# ET6801 register map
Vendor: ETMCU Inc.; File version: v0.0.1
CPU: CM7 r2p1, little endian, MPU, FPU, I-cache, D-cache, ITCM, DTCM, 4 interrupt priority bits
Registers are 32-bit, read-write, reset 0x0 unless marked. A register's access mark holds for its fields unless they carry their own. Offsets are from the block's base; [hi:lo] are bit positions; lines under a group give offsets from that group; {n}, {i} and the like mark numbered series.

## PFLASH — Provide an overview of the purpose and functionality of the peripheral: efc_cfg_pflash
Base 0x40603000
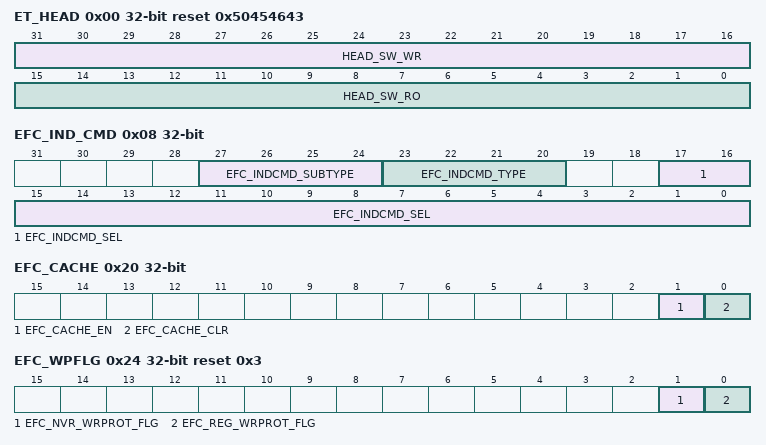
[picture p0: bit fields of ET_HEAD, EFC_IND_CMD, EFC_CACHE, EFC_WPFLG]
0x00 ET_HEAD reset 0x50454643
  [31:16] HEAD_SW_WR — 软件测试读写寄存器，硬件无访问
  [15:0] HEAD_SW_RO ro — 软件只读上报寄存器，硬件无访问,PEFC的ASICII 码表示
0x04 EFC_MEM_BASE
  [31:0] EFC_MEM_BASE_ADDR — EFC模块数据空间在系统的偏移地址
0x08 EFC_IND_CMD
  [27:24] EFC_INDCMD_SUBTYPE — sub选择类型； 0: NVR_CFG； 1: NVR； 2: RDN； 3: Main； 4: Main+RDN; //只在chip/block擦除时才能配置，并且block擦除不能选择Block retry擦除 5: Main+RDN+NVR; //只在chip擦除时才能配置 others: reserved.
  [23:20] EFC_INDCMD_TYPE — 指令类型： 0:Write; 1:Sector擦除; 2:Sector retry擦除; 3:Block擦除; 4:Block retry擦除;//只在所选Block区域无Bad Sector（即无RDN替换）时才能选择，并且不能选择Main+RDN 5:Chip擦除; 6:Normal Read; 7:Recall Read; 8:VREAD0; 9:VREAD1 10:VREAD1 check for Sector; 11:VREAD1 check for Block; 12:Sread0; 13:Sread1; default: NA；
  [17:0] EFC_INDCMD_SEL — 地址选择： 当指令类型为Read或Write时，该域为8byte单位的地址； 当指令类型为Sector/Block擦除或VREAD1时，该域为8byte单位的地址； 当指令类型为Chip擦除时，固定为0； 当sub选择类型==0: NVR_CFG时，该域为16byte单位的地址; 当sub选择类型==2: RDN时，该域为8byte单位的地址，该域为[17:14]: 4'b0001：选择RDN0，4'b0010：选择RDN1；4'b0100：选择RDN2，4'b1000：选择RDN3，[7:0]选择RDN Sector内部地址；其它bit不关注; 当sub选择类型==2:MAIN_RDN且当选择类型==3:Block擦除时，该域为8byte单位的地址，该域为[11:8]: 4'bxxx1：选择RDN0，4'bxx1x：选择RDN1；4'bx1xx：选择RDN2，4'b1xxx：选择RDN3，可同时选择多个RDN，[17:12]选择Block地址；其它bit不关注
0x0C EFC_IND_STS ro reset 0x1
  [1:0] EFC_INDIRECT_STS — 状态返回，只读： 0: 正在操作；1: 操作完成(OK)；2: 操作完成(ERR)；other: Reserved。 硬件也会查看该状态，在正在操作过程中，不会接受下一个指令，并会上报不一致错误；
0x10 EFC_IND_WD0
  [31:0] EFC_INDIRECT_WDATA0 — 低32bit写数据，如果涉及到byte级的操作，软件写入该寄存器时，不操作部分置1
0x14 EFC_IND_WD1
  [31:0] EFC_INDIRECT_WDATA1 — 高32bit写数据，如果涉及到byte级的操作，软件写入该寄存器时，不操作部分置1
0x18 EFC_IND_RD0 ro
  [31:0] EFC_INDIRECT_RDATA0 — 低32bit返回数据
0x1C EFC_IND_RD1 ro
  [31:0] EFC_INDIRECT_RDATA1 — 高32bit返回数据
0x20 EFC_CACHE
  [1] EFC_CACHE_EN — Cache使能； 0: Cache功能不打开； 1: Cache功能打开；
  [0] EFC_CACHE_CLR — Cache清空，硬件自清零； 0: Cache不清空； 1: Cache清空，下一拍硬件自清零；
0x24 EFC_WPFLG reset 0x3
  [1] EFC_NVR_WRPROT_FLG — NVR写保护标记，软件写1，硬件写0
  [0] EFC_REG_WRPROT_FLG — 寄存器写保护标记，软件写1，硬件写0
0x28 EFC_REG_KEY1
  [31:0] EFC_REG_KEY1 — 寄存器写保护KEY1，硬件自清零
0x2C EFC_REG_KEY2
  [31:0] EFC_REG_KEY2 — 寄存器写保护KEY2，硬件自清零
0x30 EFC_NVR_KEY1
  [31:0] EFC_NVR_KEY1 — NVR写保护KEY1，硬件自清零
0x34 EFC_NVR_KEY2
  [31:0] EFC_NVR_KEY2 — NVR写保护KEY2，硬件自清零
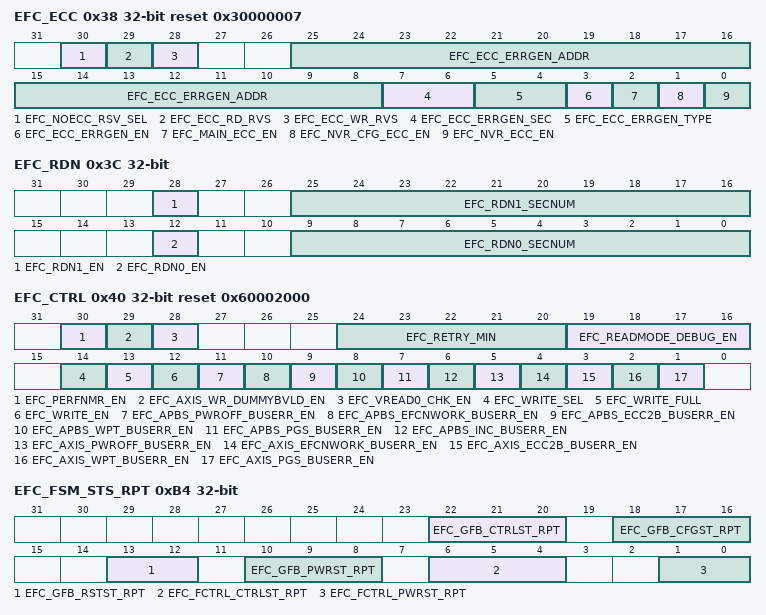
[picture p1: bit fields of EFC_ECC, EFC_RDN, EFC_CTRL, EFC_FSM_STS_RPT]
0x38 EFC_ECC reset 0x30000007
  [30] EFC_NOECC_RSV_SEL — ECC功能使能关闭时，8bit8全1插入位置选择： 0:除RSV3bi外，最高8bit，即3bit RSV+8bit ECC+ 64bit DATA； 1:最低8bit，即3bit RSV+64bit DATA+8bit ECC；
  [29] EFC_ECC_RD_RVS — ECC读翻转开启使能；
  [28] EFC_ECC_WR_RVS — ECC写翻转开启使能； Note:ECC读写翻转功能需要同时使能和不使能，并且在开启ECC写入数据之后，必须首先擦除数据才能修改，在开启ECC读写翻转时，可对擦除后的地址直接读取并且不会触发ECC错误告警。
  [25:8] EFC_ECC_ERRGEN_ADDR — ECC错误注入对应地址
  [7:6] EFC_ECC_ERRGEN_SEC — 地址对应sector范围； 1: NVR； 3: Main； other：reserved
  [5:4] EFC_ECC_ERRGEN_TYPE — ECC错误注入类型： 0：单bit错误； 1：2bit错误； other：更多bit错误；
  [3] EFC_ECC_ERRGEN_EN — ECC错误注入使能 1'b0：不打开ECC错误注入； 1'b1：打开ECC错误注入；
  [2] EFC_MAIN_ECC_EN — Main空间ECC功能使能开关； 0: ECC功能不使能； 1: ECC功能使能； Note：当使能注错功能时，对应注错地址需要先进行打开ecc使能后编程初始化，以确保注错地址本身存储的数据是ecc正确，否则上报的注错地址，不确定是其本身存储的数据ecc错误上报，还是注错导致的ecc错误地址上报；或者同时开启ECC读写翻转
  [1] EFC_NVR_CFG_ECC_EN — NVR_CFG空间ECC功能使能开关； 0: ECC功能不使能； 1: ECC功能使能； Note：NVR_CFG空间必须奇偶ROW对应地址的数据一致，对应bit才能读出确定值。
  [0] EFC_NVR_ECC_EN — NVR空间ECC功能使能开关； 0: ECC功能不使能； 1: ECC功能使能；
0x3C EFC_RDN
  [28] EFC_RDN1_EN — Redundancy sector的使能开关; 0: Redundancy sector使能关闭; 1: Redundancy sector使能打开；
  [25:16] EFC_RDN1_SECNUM — RDN1对应的Main空间sector number
  [12] EFC_RDN0_EN — Redundancy sector的使能开关; 0: Redundancy sector使能关闭; 1: Redundancy sector使能打开；
  [9:0] EFC_RDN0_SECNUM — RDN0对应的Main空间sector number
0x40 EFC_CTRL reset 0x60002000
  [30] EFC_PERFNMR_EN — EFC数据总线读性能模式使能； 0：数据总线读等待FLASH时钟上升沿进入读状态； 1：数据总线读提前FLASH时钟上升沿两个EFC时钟周期进入读状态；
  [29] EFC_AXIS_WR_DUMMYBVLD_EN — 数据总线写返回dummy bvlid使能； 0：数据总线写不返回dummy bvlid，数据写入FLASH之后再返回bvlid； 1：数据总线写命令接收后直接返回dummy bvlid；
  [28] EFC_VREAD0_CHK_EN — AXI/APB总线对FLASH编程后自动VRAD0读CHECK使能 0: 不进行VRAD0读CHECK； 1: 进行VRAD0读CHECK；
  [24:20] EFC_RETRY_MIN — 配置Flash retry擦除的最少次数；
  [19:16] EFC_READMODE_DEBUG_EN — AXI读FLASH替换为VREAD0/1、SREAD0/1读使能； 4'b0000: AXI读不进行替换，AXI为Normal READ； 4'b0001: AXI读替换为VREAD0； 4'b0010: AXI读替换为VREAD1； 4'b0100: AXI读替换为SREAD0； 4'b1000: AXI读替换为SREAD1； others: AXI读不进行替换
  [14] EFC_WRITE_SEL — FLASH写36bit选择； 0:写低36bit有效数据，高36bit写全1； 1:写高36bit有效数据，低36bit写全1； 注：，cfg_efc_write_full配置为0，硬件一次写36bit有效数据时有效，并且软件对应为AXI 8Bytes地址的低36bits；
  [13] EFC_WRITE_FULL — FLASH全写72bit使能； 0：硬件一次写36bit有效数据，另外36bit写全1； 1: 硬件一次性写72bit有效数据；
  [12] EFC_WRITE_EN — 配置EFC允许对Flash（Main / Redundancy）进行写/擦除操作； 0: 不允许对Flash进行写/擦除操作； 1: 允许对Flash进行写/擦除操作；
  [11] EFC_APBS_PWROFF_BUSERR_EN — 配置总线错误产生使能； 0: 在Flash未工作时的后续操作，APB总线不反馈Error Resp； 1: 在Flash未工作时的后续操作，APB总线反馈Error Resp；
  [10] EFC_APBS_EFCNWORK_BUSERR_EN — 配置总线错误产生使能； 0: 在EFC未工作时的后续操作，APB总线不反馈Error Resp； 1: 在EFC未工作时的后续操作，APB总线反馈Error Resp；
  [9] EFC_APBS_ECC2B_BUSERR_EN — 配置总线错误产生使能； 0: 在EFC未工作时的后续操作，APB总线不反馈Error Resp； 1: 在EFC未工作时的后续操作，APB总线反馈Error Resp；
  [8] EFC_APBS_WPT_BUSERR_EN — 配置总线错误产生使能； 0: 在发生wrp错误时，APB总线不反馈Error Resp； 1: 发生wrp错误时，APB总线反馈Error Resp；
  [7] EFC_APBS_PGS_BUSERR_EN — 配置总线错误产生使能； 0: 在发生pgs错误时，APB总线不反馈Error Resp； 1: 发生pgs错误时，APB总线反馈Error Resp；
  [6] EFC_APBS_INC_BUSERR_EN — 配置总线错误产生使能； 0: 在发生inc错误时，APB总线不反馈Error Resp； 1: 发生inc错误时，APB总线反馈Error Resp；
  [5] EFC_AXIS_PWROFF_BUSERR_EN — 数据总线错误产生使能； 0: 在Flash未工作时的后续操作，AXI总线不反馈Error Resp； 1: 在Flash未工作时的后续操作，AXI总线反馈Error Resp；
  [4] EFC_AXIS_EFCNWORK_BUSERR_EN — 数据总线错误产生使能； 0: 在EFC未工作时的后续操作，AXI总线不反馈Error Resp； 1: 在EFC未工作时的后续操作，AXI总线反馈Error Resp；
  [3] EFC_AXIS_ECC2B_BUSERR_EN — 数据总线错误产生使能； 0: 在EFC未工作时的后续操作，AXI总线不反馈Error Resp； 1: 在EFC未工作时的后续操作，AXI总线反馈Error Resp；
  [2] EFC_AXIS_WPT_BUSERR_EN — 数据总线错误产生使能； 0: 在发生wrp错误时，AXI总线不反馈Error Resp； 1: 发生wrp错误时，AXI总线反馈Error Resp；
  [1] EFC_AXIS_PGS_BUSERR_EN — 数据总线错误产生使能； 0: 在发生pgs错误时，AXI总线不反馈Error Resp； 1: 发生pgs错误时，AXI总线反馈Error Resp；
0x44 EFC_SYSBOOT reset 0x3E800
  [31:0] EFC_BOOT_TIMEOUT_MAX — Flash自启动最大超时设置； 默认为25MHz工作时钟、flash 25M timing参数配置下，启动时间的2倍；启动时间约72us，总长按80us计算，也就是在25MHz工作时钟下160us所占的cycle数，为4000；并且最快控制器工作在200M（time_out的计数器以最快频率计数），而颗粒处工作在25M（返回时间最慢）时，以时钟偏差50%角度设置该time_out的conter值，也不会超时， cfg_efc_boot_timeout_max=4000*(200M/25M)*(100M/12.5M)=128000;
0x48 EFC_INT_EN reset 0x204000
  [21:0] EFC_INT_EN — bit[14] - boot_timeout默认使能 bit[21] -- setcfg_fail默认使能
0x4C EFC_INT_MASK reset 0x280000
  [21:0] EFC_INT_MASK — bit[19] -- axim_cmd_err 默认mask，只做告警使用 bit[21] -- setcfg_fail默认mask，只做告警使用
0x50 EFC_INT_FORCE_IND
  [21:0] EFC_INT_FORCE_IND
0x54 EFC_INT_CLR
  [21:0] EFC_INT_CLR
0x58 EFC_INT_RAW_RPT ro
  [21:0] EFC_INT_RAW
0x5C EFC_INT_STATUS_RPT ro
  [21:0] EFC_INT_STATUS
{0x60+4i} EFC_DEBUG[{i}] (i=0..18) group — CFG_EFC_DEBUG
  0x00 DEBUG ro
    [31:0] EFC_DEBUG_INFO
0xAC EFC_DBG_STS ro
  [31:0] EFC_DBG_STS — [31:24] - intrd_rsved_cnt[7:0] [18:16] - intwr_rsved_cnt[2:0] [15:8] - busrd_rsved_cnt[7:0] [7:6] - s40_fctrl_idle - Flash无操作 [2:0] - buswr_rsved_cnt[2:0]
0xB0 EFC_RSV
  [31:0] EFC_RSVED — reserved register
0xB4 EFC_FSM_STS_RPT ro
  [22:20] EFC_GFB_CTRLST_RPT — EFC_GFB模块CTRL状态，只读： 0：等待EFC GFB POWER&RESET启动结束（WAITNG） 1：空闲（IDLE）； 2：写（WR）； 3：写RESP握手（WRESP）； 4：读（RD）； 5：擦除/VREAD RESP握手（BRESP）；
  [18:16] EFC_GFB_CFGST_RPT — EFC_GFB模块CFG_PROC状态，只读: 0：空闲（IDLE）； 1：APB间接读（READ）； 2：APB间接写（WRITE）； 3：APB全片擦除（ALLFCE）； other：APB间接sector/block/chip擦除、Vread1检查（OTHER）。
  [13:12] EFC_GFB_RSTST_RPT — EFC_GFB模块RESET状态，只读： 0：空闲（IDLE）； other：正常工作（WORKING）。
  [10:8] EFC_GFB_PWRST_RPT — EFC_GFB模块POWER上电状态，只读： 0：掉电（POWER OFF）； 1：读NVR_CFG（RD NVRC）； 2：写CFG寄存器（SETC）； 3：读CFG寄存器（RDC）；（车规FLASH MACRO新增操作） other：正常工作（WORKING）。
  [6:4] EFC_FCTRL_CTRLST_RPT — S40_FCTRL模块CTRL状态，只读： 0：空闲（IDLE）； 1：FLASH读（READ）； 2：FLASH写（WRITE）； 3：FLASH写CFG寄存器（SETCFG）； other：FLASH擦除（ERASE）。
  [1:0] EFC_FCTRL_PWRST_RPT — S40_FCTRL模块POWER状态，只读： 0：FLASH空闲（IDLE）； 1：FLASH上电（POWER ON）； 2：FLASH正常工作（WORKING）； other：FLASH深度睡眠（DPD Deep Power Down）。
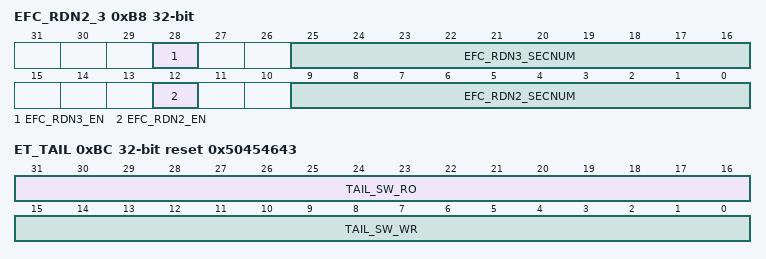
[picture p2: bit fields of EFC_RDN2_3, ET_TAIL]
0xB8 EFC_RDN2_3
  [28] EFC_RDN3_EN — Redundancy sector的使能开关; 0: Redundancy sector使能关闭; 1: Redundancy sector使能打开；
  [25:16] EFC_RDN3_SECNUM — RDN3对应的Main空间sector number
  [12] EFC_RDN2_EN — Redundancy sector的使能开关; 0: Redundancy sector使能关闭; 1: Redundancy sector使能打开；
  [9:0] EFC_RDN2_SECNUM — RDN2对应的Main空间sector number
0xBC ET_TAIL reset 0x50454643
  [31:16] TAIL_SW_RO ro — 软件只读上报寄存器，硬件无访问
  [15:0] TAIL_SW_WR — 软件测试读写寄存器，硬件无访问,PEFC的ASICII 码表示
